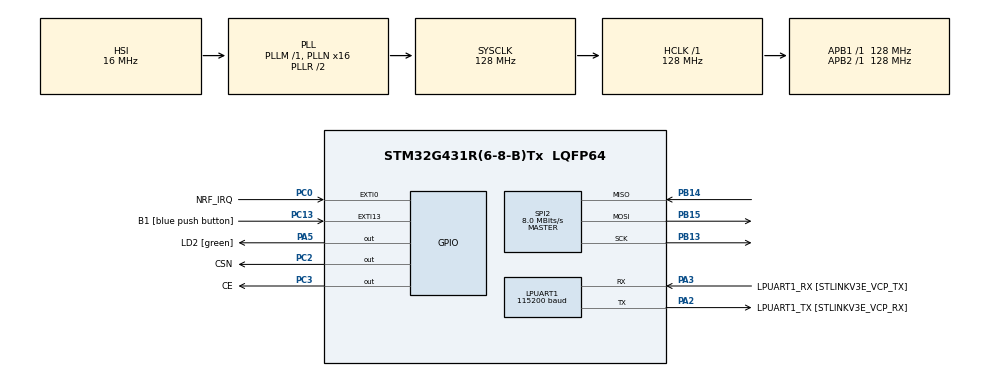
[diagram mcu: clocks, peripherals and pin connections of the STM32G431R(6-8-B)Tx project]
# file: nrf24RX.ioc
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LPUART1.BaudRate=115200
LPUART1.WordLength=UART_WORDLENGTH_8B
Mcu.Family=STM32G4
Mcu.Name=STM32G431R(6-8-B)Tx
Mcu.Package=LQFP64
NVIC.PriorityGroup=NVIC_PRIORITYGROUP_4
PA13.GPIO_Label=T_SWDIO
PA13.Mode=Serial_Wire
PA13.Signal=SYS_JTMS-SWDIO
PA14.GPIO_Label=T_SWCLK
PA14.Mode=Serial_Wire
PA14.Signal=SYS_JTCK-SWCLK
PA2.GPIO_Label=LPUART1_TX [STLINKV3E_VCP_RX]
PA2.Mode=Asynchronous
PA2.Signal=LPUART1_TX
PA3.GPIO_Label=LPUART1_RX [STLINKV3E_VCP_TX]
PA3.Mode=Asynchronous
PA3.Signal=LPUART1_RX
PA5.GPIO_Label=LD2 [green]
PA5.Signal=GPIO_Output
PB13.GPIO_Speed=GPIO_SPEED_FREQ_VERY_HIGH
PB13.Mode=Full_Duplex_Master
PB13.Signal=SPI2_SCK
PB14.GPIO_Speed=GPIO_SPEED_FREQ_VERY_HIGH
PB14.Mode=Full_Duplex_Master
PB14.Signal=SPI2_MISO
PB15.GPIO_Speed=GPIO_SPEED_FREQ_VERY_HIGH
PB15.Mode=Full_Duplex_Master
PB15.Signal=SPI2_MOSI
PB3.GPIO_Label=T_SWO
PB3.Signal=SYS_JTDO-SWO
PC0.GPIO_Label=NRF_IRQ
PC0.GPIO_ModeDefaultEXTI=GPIO_MODE_IT_FALLING
PC0.GPIO_PuPd=GPIO_PULLUP
PC0.Signal=GPXTI0
PC13.GPIO_Label=B1 [blue push button]
PC13.Signal=GPXTI13
PC14-OSC32_IN.Mode=LSE-External-Oscillator
PC14-OSC32_IN.Signal=RCC_OSC32_IN
PC15-OSC32_OUT.Mode=LSE-External-Oscillator
PC15-OSC32_OUT.Signal=RCC_OSC32_OUT
PC2.GPIO_Label=CSN
PC2.GPIO_Speed=GPIO_SPEED_FREQ_VERY_HIGH
PC2.Signal=GPIO_Output
PC3.GPIO_Label=CE
PC3.GPIO_Speed=GPIO_SPEED_FREQ_VERY_HIGH
PC3.Signal=GPIO_Output
PF0-OSC_IN.Mode=HSE-External-Oscillator
PF0-OSC_IN.Signal=RCC_OSC_IN
PF1-OSC_OUT.Mode=HSE-External-Oscillator
PF1-OSC_OUT.Signal=RCC_OSC_OUT
ProjectManager.HeapSize=0x200
ProjectManager.StackSize=0x400
ProjectManager.TargetToolchain=STM32CubeIDE
RCC.ADC12Freq_Value=128000000
RCC.AHBFreq_Value=128000000
RCC.APB1Freq_Value=128000000
RCC.APB1TimFreq_Value=128000000
RCC.APB2Freq_Value=128000000
RCC.APB2TimFreq_Value=128000000
RCC.CortexFreq_Value=128000000
RCC.EXTERNAL_CLOCK_VALUE=12288000
RCC.HCLKFreq_Value=128000000
RCC.HSE_VALUE=24000000
RCC.HSI48_VALUE=48000000
RCC.HSI_VALUE=16000000
RCC.PLLN=16
RCC.RTCClockSelection=RCC_RTCCLKSOURCE_LSE
RCC.SYSCLKFreq_VALUE=128000000
RCC.SYSCLKSource=RCC_SYSCLKSOURCE_PLLCLK
RCC.USBFreq_Value=128000000
RCC.VCOOutputFreq_Value=256000000
SPI2.BaudRatePrescaler=SPI_BAUDRATEPRESCALER_16
SPI2.CalculateBaudRate=8.0 MBits/s
SPI2.DataSize=SPI_DATASIZE_8BIT
SPI2.Direction=SPI_DIRECTION_2LINES
SPI2.Mode=SPI_MODE_MASTER
SPI2.NSSPMode=SPI_NSS_PULSE_DISABLE
SPI2.VirtualType=VM_MASTER
VP_SYS_VS_DBSignals.Mode=DisableDeadBatterySignals
board=NUCLEO-G431RB

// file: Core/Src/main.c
/* USER CODE BEGIN Header */
/**
  ******************************************************************************
  * @file           : main.c
  * @brief          : Código actualizado para el receptor NRF24 sin usar formato de float
  *                   en printf. Se utiliza una función auxiliar para convertir floats.
  ******************************************************************************
  * @attention
  *
  * Nota: Se ha implementado la función floatToString para evitar el uso de "%.2f".
  * Esto es útil si no se ha habilitado el soporte para formateo de float.
  *
  ******************************************************************************
  */
/* USER CODE END Header */

#include "main.h"
#include <stdio.h>
#include <string.h>
#include <stdlib.h>
#include <math.h>
#include "nrf24.h"

UART_HandleTypeDef hlpuart1;
SPI_HandleTypeDef hspi2;

/* USER CODE BEGIN PV */
char uart_msg[100];
uint8_t RxAddress[6] = {0xE7, 0xE7, 0xE7, 0xE7, 0xE7};
float receivedData[8];
/* USER CODE END PV */

void SystemClock_Config(void);
static void MX_GPIO_Init(void);
static void MX_LPUART1_UART_Init(void);
static void MX_SPI2_Init(void);

/* USER CODE BEGIN PFP */
void print(const char *uart_buffer);
void printHex(uint8_t value);
void printAddress(uint8_t *address, uint8_t size);
void printPayload(float *data, uint8_t size);
void floatToString(float value, char *buffer);
/* USER CODE END PFP */

void print(const char *uart_buffer) {
    sprintf(uart_msg, "%s\n\r", uart_buffer);
    HAL_UART_Transmit(&hlpuart1, (uint8_t*)uart_msg, strlen(uart_msg), HAL_MAX_DELAY);
}

void printHex(uint8_t value) {
    sprintf(uart_msg, "%02X ", value);
    HAL_UART_Transmit(&hlpuart1, (uint8_t*)uart_msg, strlen(uart_msg), HAL_MAX_DELAY);
}

void printAddress(uint8_t *address, uint8_t size) {
    for (uint8_t i = 0; i < size; i++) {
        printHex(address[i]);
    }
    print("");
}

void floatToString(float value, char *buffer) {
    if(value < 0) {
        *buffer++ = '-';
        value = -value;
    }
    int intPart = (int)value;
    int fracPart = (int)((value - intPart) * 100);
    sprintf(buffer, "%d.%02d", intPart, fracPart);
}

void printPayload(float *data, uint8_t size) {
    char floatStr[20];
    for (uint8_t i = 0; i < size; i++) {
        floatToString(data[i], floatStr);
        sprintf(uart_msg, "Data[%d]: %s\n\r", i, floatStr);
        HAL_UART_Transmit(&hlpuart1, (uint8_t*)uart_msg, strlen(uart_msg), HAL_MAX_DELAY);
    }
}

int main(void)
{
    HAL_Init();
    SystemClock_Config();
    MX_GPIO_Init();
    MX_LPUART1_UART_Init();
    MX_SPI2_Init();

    NRF24_Init();
    NRF24_RxMode(RxAddress, 100);

    print("Receiver Address:");
    printAddress(RxAddress, 5);

    while (1)
    {
        uint8_t status = nrf24_ReadReg(STATUS);
        sprintf(uart_msg, "Status: %02X\n\r", status);
        HAL_UART_Transmit(&hlpuart1, (uint8_t*)uart_msg, strlen(uart_msg), HAL_MAX_DELAY);

        uint8_t pipe_number = (status >> 1) & 0x07;
        sprintf(uart_msg, "Pipe number: %d\n\r", pipe_number);
        HAL_UART_Transmit(&hlpuart1, (uint8_t*)uart_msg, strlen(uart_msg), HAL_MAX_DELAY);

        if (isDataAvailable(2))
        {
            NRF24_Receive((uint8_t*)receivedData);
            print("Received Payload:");
            printPayload(receivedData, 8);
            nrf24_WriteReg(STATUS, (1 << 6));
            HAL_GPIO_TogglePin(GPIOA, GPIO_PIN_5);
        }
        else
        {
            print("No data available");
        }

        HAL_Delay(100);
    }
}

void SystemClock_Config(void)
{
    RCC_OscInitTypeDef RCC_OscInitStruct = {0};
    RCC_ClkInitTypeDef RCC_ClkInitStruct = {0};

    HAL_PWREx_ControlVoltageScaling(PWR_REGULATOR_VOLTAGE_SCALE1);

    RCC_OscInitStruct.OscillatorType = RCC_OSCILLATORTYPE_HSI;
    RCC_OscInitStruct.HSIState = RCC_HSI_ON;
    RCC_OscInitStruct.HSICalibrationValue = RCC_HSICALIBRATION_DEFAULT;
    RCC_OscInitStruct.PLL.PLLState = RCC_PLL_ON;
    RCC_OscInitStruct.PLL.PLLSource = RCC_PLLSOURCE_HSI;
    RCC_OscInitStruct.PLL.PLLM = RCC_PLLM_DIV1;
    RCC_OscInitStruct.PLL.PLLN = 16;
    RCC_OscInitStruct.PLL.PLLP = RCC_PLLP_DIV2;
    RCC_OscInitStruct.PLL.PLLQ = RCC_PLLQ_DIV2;
    RCC_OscInitStruct.PLL.PLLR = RCC_PLLR_DIV2;
    if (HAL_RCC_OscConfig(&RCC_OscInitStruct) != HAL_OK) {
        Error_Handler();
    }

    RCC_ClkInitStruct.ClockType = RCC_CLOCKTYPE_HCLK|RCC_CLOCKTYPE_SYSCLK |
                                  RCC_CLOCKTYPE_PCLK1|RCC_CLOCKTYPE_PCLK2;
    RCC_ClkInitStruct.SYSCLKSource = RCC_SYSCLKSOURCE_PLLCLK;
    RCC_ClkInitStruct.AHBCLKDivider = RCC_SYSCLK_DIV1;
    RCC_ClkInitStruct.APB1CLKDivider = RCC_HCLK_DIV1;
    RCC_ClkInitStruct.APB2CLKDivider = RCC_HCLK_DIV1;

    if (HAL_RCC_ClockConfig(&RCC_ClkInitStruct, FLASH_LATENCY_4) != HAL_OK) {
        Error_Handler();
    }
}

static void MX_LPUART1_UART_Init(void)
{
    hlpuart1.Instance = LPUART1;
    hlpuart1.Init.BaudRate = 115200;
    hlpuart1.Init.WordLength = UART_WORDLENGTH_8B;
    hlpuart1.Init.StopBits = UART_STOPBITS_1;
    hlpuart1.Init.Parity = UART_PARITY_NONE;
    hlpuart1.Init.Mode = UART_MODE_TX_RX;
    hlpuart1.Init.HwFlowCtl = UART_HWCONTROL_NONE;
    hlpuart1.Init.OneBitSampling = UART_ONE_BIT_SAMPLE_DISABLE;
    hlpuart1.Init.ClockPrescaler = UART_PRESCALER_DIV1;
    hlpuart1.AdvancedInit.AdvFeatureInit = UART_ADVFEATURE_NO_INIT;
    if (HAL_UART_Init(&hlpuart1) != HAL_OK) {
        Error_Handler();
    }
    if (HAL_UARTEx_SetTxFifoThreshold(&hlpuart1, UART_TXFIFO_THRESHOLD_1_8) != HAL_OK) {
        Error_Handler();
    }
    if (HAL_UARTEx_SetRxFifoThreshold(&hlpuart1, UART_RXFIFO_THRESHOLD_1_8) != HAL_OK) {
        Error_Handler();
    }
    if (HAL_UARTEx_DisableFifoMode(&hlpuart1) != HAL_OK) {
        Error_Handler();
    }
}

static void MX_SPI2_Init(void)
{
    hspi2.Instance = SPI2;
    hspi2.Init.Mode = SPI_MODE_MASTER;
    hspi2.Init.Direction = SPI_DIRECTION_2LINES;
    hspi2.Init.DataSize = SPI_DATASIZE_8BIT;
    hspi2.Init.CLKPolarity = SPI_POLARITY_LOW;
    hspi2.Init.CLKPhase = SPI_PHASE_1EDGE;
    hspi2.Init.NSS = SPI_NSS_SOFT;
    hspi2.Init.BaudRatePrescaler = SPI_BAUDRATEPRESCALER_16;
    hspi2.Init.FirstBit = SPI_FIRSTBIT_MSB;
    hspi2.Init.TIMode = SPI_TIMODE_DISABLE;
    hspi2.Init.CRCCalculation = SPI_CRCCALCULATION_DISABLE;
    hspi2.Init.CRCPolynomial = 7;
    hspi2.Init.CRCLength = SPI_CRC_LENGTH_DATASIZE;
    hspi2.Init.NSSPMode = SPI_NSS_PULSE_DISABLE;
    if (HAL_SPI_Init(&hspi2) != HAL_OK) {
        Error_Handler();
    }
}

static void MX_GPIO_Init(void)
{
    GPIO_InitTypeDef GPIO_InitStruct = {0};

    __HAL_RCC_GPIOC_CLK_ENABLE();
    __HAL_RCC_GPIOF_CLK_ENABLE();
    __HAL_RCC_GPIOA_CLK_ENABLE();
    __HAL_RCC_GPIOB_CLK_ENABLE();

    HAL_GPIO_WritePin(GPIOC, CSN_Pin|CE_Pin, GPIO_PIN_RESET);
    HAL_GPIO_WritePin(LD2_GPIO_Port, LD2_Pin, GPIO_PIN_RESET);

    GPIO_InitStruct.Pin = B1_Pin;
    GPIO_InitStruct.Mode = GPIO_MODE_IT_RISING;
    GPIO_InitStruct.Pull = GPIO_NOPULL;
    HAL_GPIO_Init(B1_GPIO_Port, &GPIO_InitStruct);

    GPIO_InitStruct.Pin = NRF_IRQ_Pin;
    GPIO_InitStruct.Mode = GPIO_MODE_IT_FALLING;
    GPIO_InitStruct.Pull = GPIO_PULLUP;
    HAL_GPIO_Init(NRF_IRQ_GPIO_Port, &GPIO_InitStruct);

    GPIO_InitStruct.Pin = CSN_Pin|CE_Pin;
    GPIO_InitStruct.Mode = GPIO_MODE_OUTPUT_PP;
    GPIO_InitStruct.Pull = GPIO_NOPULL;
    GPIO_InitStruct.Speed = GPIO_SPEED_FREQ_VERY_HIGH;
    HAL_GPIO_Init(GPIOC, &GPIO_InitStruct);

    GPIO_InitStruct.Pin = LD2_Pin;
    GPIO_InitStruct.Mode = GPIO_MODE_OUTPUT_PP;
    GPIO_InitStruct.Pull = GPIO_NOPULL;
    GPIO_InitStruct.Speed = GPIO_SPEED_FREQ_LOW;
    HAL_GPIO_Init(LD2_GPIO_Port, &GPIO_InitStruct);
}

void Error_Handler(void)
{
    __disable_irq();
    while (1) {}
}
